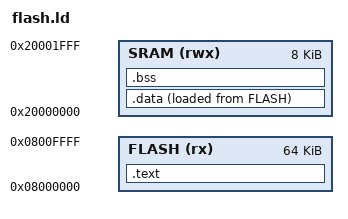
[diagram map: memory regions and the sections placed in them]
/* Linker script for GD32F150C8T6 Flash execution (64KB Flash, 8KB SRAM) */
MEMORY
{
    FLASH (rx)  : ORIGIN = 0x08000000, LENGTH = 64K
    SRAM  (rwx) : ORIGIN = 0x20000000, LENGTH = 8K
}

ENTRY(Reset_Handler)

SECTIONS
{
    .text : {
        KEEP(*(.isr_vector))
        *(.text*)
        *(.rodata*)
        . = ALIGN(4);
        _etext = .;
    } > FLASH

    _sidata = LOADADDR(.data);

    .data : {
        . = ALIGN(4);
        _sdata = .;
        *(.data*)
        . = ALIGN(4);
        _edata = .;
    } > SRAM AT > FLASH

    .bss : {
        . = ALIGN(4);
        _sbss = .;
        *(.bss*)
        *(COMMON)
        . = ALIGN(4);
        _ebss = .;
    } > SRAM

    _stack_top = ORIGIN(SRAM) + LENGTH(SRAM);

    /DISCARD/ : {
        *(.ARM.*)
        *(.comment)
    }
}
